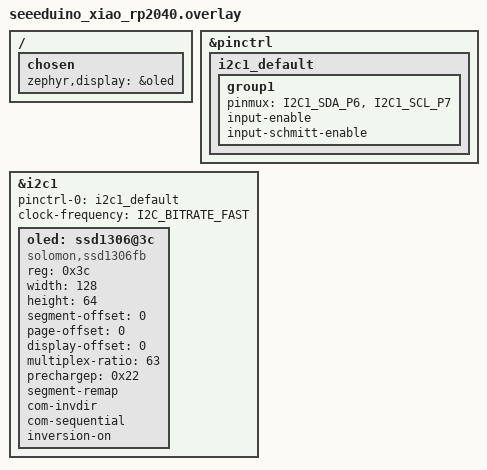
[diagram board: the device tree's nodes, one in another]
/**
 * Generated by Shield Wizard for ZMK
 * Applies to part "unibody" with controller "xiao_rp2040"
 */

// pin control for i2c1
// SDA on D4
// SCL on D5
&pinctrl {
    i2c1_default: i2c1_default {
        group1 {
            pinmux = <I2C1_SDA_P6>, <I2C1_SCL_P7>;
            input-enable;
            input-schmitt-enable;
        };
    };
};
&i2c1 {
    status = "okay";
    pinctrl-0 = <&i2c1_default>;
    pinctrl-names = "default";
    clock-frequency = <I2C_BITRATE_FAST>;
};

// devices on i2c1

&i2c1 {
    oled: ssd1306@3c {
        compatible = "solomon,ssd1306fb";
        reg = <0x3c>;
        width = <128>;
        height = <64>;

        segment-offset = <0>;
        page-offset = <0>;
        display-offset = <0>;
        multiplex-ratio = <63>;
        prechargep = <0x22>;
        segment-remap;
        com-invdir;
        com-sequential;
        inversion-on;
    };
};
/ {
    chosen {
        zephyr,display = &oled;
    };
};
